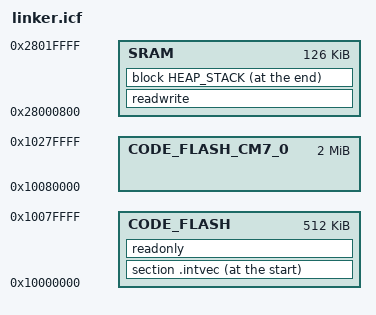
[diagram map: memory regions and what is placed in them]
/*******************************************************************************
* \file xmc7200d_x8384_cm0plus.icf
* \version 1.0.0
*
* Linker file for the IAR compiler.
*
* The main purpose of the linker script is to describe how the sections in the
* input files should be mapped into the output file, and to control the memory
* layout of the output file.
*
* \note The entry point is fixed and starts at 0x10000000. The valid application
* image should be placed there.
*
* \note The linker files included with the PDL template projects must be generic
* and handle all common use cases. Your project may not use every section
* defined in the linker files. In that case you may see warnings during the
* build process. In your project, you can simply comment out or remove the
* relevant code in the linker file.
*
********************************************************************************
* \copyright
* Copyright 2021 Cypress Semiconductor Corporation
* SPDX-License-Identifier: Apache-2.0
*
* Licensed under the Apache License, Version 2.0 (the "License");
* you may not use this file except in compliance with the License.
* You may obtain a copy of the License at
*
*     http://www.apache.org/licenses/LICENSE-2.0
*
* Unless required by applicable law or agreed to in writing, software
* distributed under the License is distributed on an "AS IS" BASIS,
* WITHOUT WARRANTIES OR CONDITIONS OF ANY KIND, either express or implied.
* See the License for the specific language governing permissions and
* limitations under the License.
*******************************************************************************/
define symbol RAMVECTORS_ALIGNMENT              = 128;

define symbol sram_start_reserve                = 0;
define symbol sram_private_for_srom             = 0x00000800; /* Private SRAM for SROM (e.g. API processing). Reserved at the beginning */

define symbol cm0plus_sram_reserve              = 0x00020000; /* cm0 sram size */
define symbol cm0plus_code_flash_reserve        = 0x00080000; /* cm7_0 sram size */
define symbol cm7_0_code_flash_reserve          = 0x00200000;

define symbol sram_base_address                 = 0x28000000;
define symbol code_flash_base_address           = 0x10000000;
define symbol code_flash_total_size             = 0x00080000;

define symbol ecc_init_width                    = 8; /* Most restrictive native ECC width of all "normal" memories (SRAM, DTCM, ITCM) in any Traveo II derivate is used to keep the code generic */

define symbol cm0plus_heap_reserve              = 0x00001000;
define symbol cm0plus_stack_reserve             = 0x00001000;

define symbol heap_reserve                      = cm0plus_heap_reserve;
define symbol stack_reserve                     = (cm0plus_stack_reserve + (ecc_init_width - 1)) & (~((ecc_init_width - 1))); /* Ensure that stack size is an integer multiple of ECC init width (round up) */


define symbol _base_SRAM_CM0P                   = sram_base_address + sram_start_reserve + sram_private_for_srom;
define symbol _size_SRAM_CM0P                   = cm0plus_sram_reserve - sram_start_reserve - sram_private_for_srom;
define symbol _base_CODE_FLASH_CM0P             = code_flash_base_address;
define symbol _size_CODE_FLASH_CM0P             = cm0plus_code_flash_reserve;
define symbol _base_CODE_FLASH_CM7_0            = code_flash_base_address + cm0plus_code_flash_reserve;
define symbol _size_CODE_FLASH_CM7_0            = cm7_0_code_flash_reserve;
define symbol _base_CODE_FLASH_CM7_1            = code_flash_base_address + cm0plus_code_flash_reserve + cm7_0_code_flash_reserve;
define symbol _size_CODE_FLASH_CM7_1            = code_flash_total_size - cm0plus_code_flash_reserve - cm7_0_code_flash_reserve;

/*============================================================
 * Memory definitions
 *============================================================
 */

define memory mem with size = 4G;

define region SRAM                              = mem:[from _base_SRAM_CM0P          size _size_SRAM_CM0P           ];
define region CODE_FLASH                        = mem:[from _base_CODE_FLASH_CM0P    size _size_CODE_FLASH_CM0P     ];
define region CODE_FLASH_CM7_0                  = mem:[from _base_CODE_FLASH_CM7_0   size _size_CODE_FLASH_CM7_0    ];
define region CODE_FLASH_CM7_1                  = mem:[from _base_CODE_FLASH_CM7_1   size _size_CODE_FLASH_CM7_1    ];

/*============================================================
 * Block definitions
 *============================================================
 */
define block CSTACK         with alignment = 8, size = stack_reserve { };
define block HEAP           with expanding size, alignment = 8, minimum size = heap_reserve { };
define block HEAP_STACK     { block HEAP, last block CSTACK };

/*============================================================
 * Initialization
 *============================================================
 */
initialize by copy { readwrite };
do not initialize  { section .noinit, section .intvec_ram };

/*============================================================
 * Placement
 *============================================================
 */

/* Link location specific assignment of 'readonly' type sections to either SRAM or CODE_FLASH */
/* Note: .intvec must be the first section in ROM in order for __cm7_vector_base_linker_symbol to be correctly calculated! */

place at start of CODE_FLASH  { section .intvec };
place in          CODE_FLASH  { readonly };

place in          SRAM  { readwrite };
place at end   of SRAM  { block HEAP_STACK };

keep {  section .intvec  };

/*============================================================
 * Symbols for use by application
 *============================================================
 */
/* The start of CM7_0/1 vector table is required by CM0+ application to correctly
 * set CPUSS->CM7_0/1_VECTOR_TABLE_BASE register before releasing CM7_0 or CM7_1 from reset
 */

define exported symbol __ecc_init_sram_start_address = start(SRAM);
define exported symbol __ecc_init_sram_end_address   = end(SRAM);

/* EOF */
